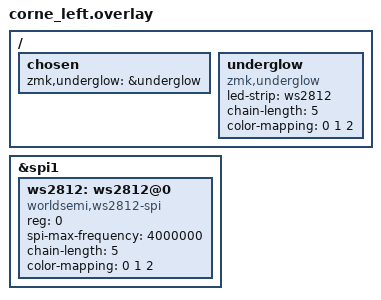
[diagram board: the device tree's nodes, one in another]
/ {
    chosen {
        zmk,underglow = &underglow;
    };

    underglow: underglow {
        compatible = "zmk,underglow";
        led-strip = <&ws2812>;
        chain-length = <5>;
        color-mapping = <0 1 2>;
    };
};

&spi1 {
    status = "okay";

    ws2812: ws2812@0 {
        compatible = "worldsemi,ws2812-spi";
        reg = <0>;
        spi-max-frequency = <4000000>;
        chain-length = <5>;
        color-mapping = <0 1 2>;
    };
};

